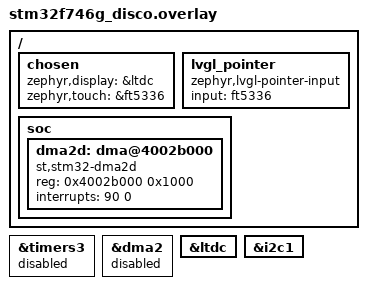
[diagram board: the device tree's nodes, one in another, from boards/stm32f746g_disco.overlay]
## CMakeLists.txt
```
# DSO-746 demo oscilloscope / spectrum analyser / generator
cmake_minimum_required(VERSION 3.20.0)

find_package(Zephyr REQUIRED HINTS $ENV{ZEPHYR_BASE})
project(dso746)

target_sources(app PRIVATE
  src/main.c
  src/ui.c
  src/acq.c
  src/acq_algo.c
  src/gen.c
  src/dsp.c
  src/dsp_math.c
  src/sim.c
)
target_include_directories(app PRIVATE src)
```

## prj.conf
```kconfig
# ---- kernel -----------------------------------------------------------
CONFIG_MAIN_STACK_SIZE=8192
CONFIG_MAIN_THREAD_PRIORITY=7
CONFIG_HEAP_MEM_POOL_SIZE=16384
CONFIG_CBPRINTF_FP_SUPPORT=y
CONFIG_FPU=y
CONFIG_LOG=y
CONFIG_LOG_MODE_DEFERRED=y
# stack diagnostics: the 5 s statistics line reports the free stack of every
# thread, so an overflow shows up in the console before it becomes a hang
CONFIG_THREAD_MONITOR=y
CONFIG_THREAD_NAME=y
CONFIG_THREAD_STACK_INFO=y
CONFIG_INIT_STACKS=y

# ---- cache: the ADC ring must not be cached, DMA does not see D-cache --
CONFIG_DCACHE=y
CONFIG_ICACHE=y
CONFIG_NOCACHE_MEMORY=y

# ---- display ----------------------------------------------------------
CONFIG_DISPLAY=y
CONFIG_STM32_LTDC=y
CONFIG_STM32_LTDC_RGB565=y
CONFIG_STM32_LTDC_FB_NUM=2

# ---- touch ------------------------------------------------------------
CONFIG_INPUT=y
CONFIG_I2C=y
CONFIG_INPUT_FT5336=y
CONFIG_INPUT_FT5336_INTERRUPT=y
# B1 USER key: demo <-> live
CONFIG_INPUT_GPIO_KEYS=y
CONFIG_GPIO=y

# ---- LVGL -------------------------------------------------------------
CONFIG_LVGL=y
CONFIG_LV_COLOR_DEPTH_16=y
CONFIG_LV_Z_MEM_POOL_SIZE=131072
CONFIG_LV_Z_VDB_SIZE=25
CONFIG_LV_Z_DOUBLE_VDB=y
# 256 KB of internal SRAM cannot hold the LVGL heap and two render buffers as
# well as the ADC ring; both go to SDRAM, the ring stays in SRAM on purpose
CONFIG_LV_Z_MEMORY_POOL_ZEPHYR_REGION=y
CONFIG_LV_Z_MEMORY_POOL_ZEPHYR_REGION_NAME="SDRAM1"
CONFIG_LV_Z_VDB_ZEPHYR_REGION=y
CONFIG_LV_Z_VDB_ZEPHYR_REGION_NAME="SDRAM1"
CONFIG_LV_Z_FLUSH_THREAD=y
CONFIG_LV_USE_CANVAS=y
CONFIG_LV_USE_LABEL=y
CONFIG_LV_FONT_UNSCII_8=y
CONFIG_LV_FONT_MONTSERRAT_12=y
CONFIG_LV_FONT_MONTSERRAT_14=y
CONFIG_LV_FONT_MONTSERRAT_20=y
# the phosphor halo is a shadow; caching the blur costs 16*16 = 256 bytes
# and removes the per-redraw recomputation
CONFIG_LV_DRAW_SW_COMPLEX=y
# ChromART (DMA2D) draw unit: fills, blends and blits are done by the
# accelerator, and the transfer-complete interrupt frees the CPU while it runs
CONFIG_LV_USE_DRAW_DMA2D=y
CONFIG_LV_DRAW_DMA2D_HAL_INCLUDE="stm32f7xx_hal.h"
# Synchronous, not interrupt-driven. In interrupt mode the draw unit waits on
# a semaphore that only the transfer-COMPLETE interrupt signals; a transfer
# that ends in a configuration or transfer error never signals it and the UI
# thread waits forever - exactly the FFT-settings freeze. The sync path polls
# the START bit, which hardware clears on completion AND on abort, so it can
# never hang. A blit is microseconds either way.
CONFIG_LV_USE_DRAW_DMA2D_INTERRUPT=n
CONFIG_LV_DRAW_SW_SHADOW_CACHE_SIZE=16

# ---- DSP --------------------------------------------------------------
CONFIG_CMSIS_DSP=y
CONFIG_CMSIS_DSP_TRANSFORM=y
CONFIG_CMSIS_DSP_COMPLEXMATH=y
CONFIG_CMSIS_DSP_FASTMATH=y
CONFIG_CMSIS_DSP_SUPPORT=y
CONFIG_CMSIS_DSP_BASICMATH=y
CONFIG_CMSIS_DSP_STATISTICS=y

# ---- console ----------------------------------------------------------
CONFIG_SERIAL=y
CONFIG_CONSOLE=y
CONFIG_UART_CONSOLE=y
```

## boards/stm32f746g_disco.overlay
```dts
/*
 * DSO-746 board overlay.
 *
 * TIM2, TIM3, ADC1, ADC3 and DMA2 are driven directly through the LL headers,
 * so the matching Zephyr drivers are kept OUT of the way: if the Zephyr DMA
 * driver owned DMA2 it would install its own handlers on the same streams
 * and the two would fight over the interrupt.
 */

/ {
	chosen {
		zephyr,display = &ltdc;
		zephyr,touch = &ft5336;
	};

	lvgl_pointer {
		compatible = "zephyr,lvgl-pointer-input";
		input = <&ft5336>;
	};
};

/* The board devicetree enables TIM3 as a PWM provider. The generator needs
 * DMA into CCR1, which the Zephyr PWM API cannot express, so we take it over. */
&timers3 {
	status = "disabled";
};

/* Left disabled on purpose - see the comment at the top. */
&dma2 {
	status = "disabled";
};

&ltdc {
	status = "okay";
};

/*
 * Chrom-ART (DMA2D). The F7 devicetree does not declare it, but LVGL's DMA2D
 * draw unit connects its interrupt through this node label, so it is declared
 * here. Base address 0x4002B000 and interrupt line 90 come from RM0385.
 */
/ {
	soc {
		dma2d: dma@4002b000 {
			compatible = "st,stm32-dma2d";
			reg = <0x4002b000 0x1000>;
			interrupts = <90 0>;
			status = "okay";
		};
	};
};

&i2c1 {
	status = "okay";
};
```

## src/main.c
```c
/*
 * Author:  Eduard
 * Project: DSO-746 - oscilloscope, FFT analyzer and signal generator
 * Repo:    https://github.com/ed1385/dso746-zephyr
 * License: MIT
 *
 * DSO-746 - entry point.
 *
 * Thread map (priority in brackets, lower number = higher priority):
 *   DMA2 stream 4 ISR   flags the finished ring half, gives a semaphore
 *   acq  [-2]           trigger search, pre-trigger extraction, frame slots
 *   main/ui [7]         LVGL, measurements, spectrum, rendering
 *   input               FT5336 interrupt -> Zephyr input -> lv_indev
 *
 * The rule that keeps the display smooth: the UI never blocks acquisition.
 * If a frame cannot be handed over it is dropped and sampling continues.
 */
#include <zephyr/kernel.h>
#include <zephyr/irq.h>
#include <soc.h>
#include <zephyr/device.h>
#include <zephyr/drivers/display.h>
#include <zephyr/logging/log.h>
#include <lvgl.h>
#include <zephyr/input/input.h>
#include <zephyr/dt-bindings/input/input-event-codes.h>

#include "app.h"

LOG_MODULE_REGISTER(main, LOG_LEVEL_INF);

/*
 * The DMA2D draw unit installs its own interrupt handler through the dma2d
 * devicetree node declared in the board overlay, so nothing is needed here.
 */

/*
 * Two rates, on purpose.
 *
 * LVGL is serviced every 10 ms. That is what makes touch feel immediate: the
 * FT5336 raises its interrupt, the Zephyr input driver queues the event, and
 * lv_timer_handler picks it up within 10 ms instead of within a frame period.
 * Key animations - the phosphor decay - also step at this rate.
 *
 * The waveform is recomputed at 50 ms. Redrawing a trace faster than 20 Hz
 * buys nothing a human can see and costs the whole FMC budget.
 */
#define TICK_MS  10
#define FRAME_MS 50

static float spec[WAVE_COLS];

#ifdef CONFIG_THREAD_STACK_INFO
static void stack_report(const struct k_thread *t, void *arg)
{
	ARG_UNUSED(arg);
	size_t unused = 0;

	if (k_thread_stack_space_get(t, &unused) == 0) {
		const char *n = k_thread_name_get((k_tid_t)t);

		LOG_INF("  stack %-10s free %5u of %5u", n ? n : "?",
			(unsigned)unused, (unsigned)t->stack_info.size);
	}
}
#endif

/*
 * B1 USER key (PI11) toggles demo <-> live. It arrives through the Zephyr
 * input subsystem as INPUT_KEY_0, the same path the touch panel uses, so the
 * gpio-keys driver keeps owning the pin and nothing fights over the GPIO.
 */
static void key_cb(struct input_event *evt, void *user_data)
{
	ARG_UNUSED(user_data);

	if (evt->type != INPUT_EV_KEY || evt->code != INPUT_KEY_0 || evt->value == 0) {
		return;
	}

	/* Spec §1.5: this runs in the input thread. It may not touch LVGL,
	 * so it only requests the switch; the UI thread applies it. */
	ui_request_demo_toggle();
}
INPUT_CALLBACK_DEFINE(NULL, key_cb, NULL);

int main(void)
{
	const struct device *disp = DEVICE_DT_GET(DT_CHOSEN(zephyr_display));

	if (!device_is_ready(disp)) {
		LOG_ERR("display not ready");
		return -ENODEV;
	}

	ui_init();
	dsp_init();
	gen_init();
	acq_init();

	ui_lock();
	acq_apply_cfg(ui_cfg());
	bool demo = ui_cfg()->demo;

	ui_unlock();
	/* the converters run from boot in both modes: switching to live then
	 * shows a live screen immediately instead of after the first sweep */
	acq_start();
	LOG_INF("boot in %s mode, B1 USER key switches", demo ? "DEMO" : "LIVE");

	display_blanking_off(disp);
	lv_timer_handler();

	uint32_t next_tick = k_uptime_get_32();
	uint32_t next_frame = next_tick;
	uint32_t frames = 0, dropped = 0, last_stat = next_tick;

	while (true) {
		/*
		 * Input first, always. lv_timer_handler() samples the touch
		 * panel; if a frame ever takes longer than a tap, the press and
		 * the release both fall between two samples and the tap is lost.
		 * So the sampling cadence is fixed at TICK_MS and is never
		 * skipped, and the frame work is what yields, not the input.
		 */
		ui_service();
		lv_timer_handler();

		uint32_t now_ms = k_uptime_get_32();

		if ((int32_t)(now_ms - next_frame) < 0) {
			next_tick += TICK_MS;
			int32_t s2 = (int32_t)(next_tick - k_uptime_get_32());

			k_msleep(s2 > 0 ? s2 : 1);
			continue;
		}
		next_frame += FRAME_MS;

		ui_lock();
		bool sim = ui_cfg()->demo;

		ui_unlock();

		struct dso_frame *f;
		bool owned = false;          /* only real frames go back to the slab */

		if (sim) {
			/* drop anything the hardware queued before the switch */
			struct dso_frame *stale;

			while ((stale = acq_take_frame(0)) != NULL) {
				acq_release_frame(stale);
			}
			/* Generate from a COPY of the settings, outside the mutex.
			 * Holding it during ~10 ms of trigonometry let the acq
			 * thread (which takes the same mutex 430 times a second
			 * at the widest span) block on it, and priority
			 * inheritance then made this thread cooperative for the
			 * whole window - a demo-only condition the live path
			 * never creates. */
			static struct dso_cfg snap;

			ui_lock();
			snap = *ui_cfg();
			ui_unlock();
			f = sim_frame(&snap);
		} else {
			f = acq_take_frame(0);     /* never block the UI thread */
			owned = (f != NULL);
		}

		struct dso_meas m = { 0 };
		const float *sp = NULL;

		if (f) {
			/* Drain anything that piled up while we were drawing and
			 * keep only the newest: showing a stale frame is worse
			 * than showing fewer of them. */
			if (owned) {
				struct dso_frame *newer;

				while ((newer = acq_take_frame(0)) != NULL) {
					acq_release_frame(f);
					f = newer;
					dropped++;
				}
			}


			ui_lock();
			uint8_t mode = ui_cfg()->mode;
			uint8_t fsrc = ui_cfg()->fft.source;
			uint8_t win = ui_cfg()->fft.window;
			bool meas_on = ui_cfg()->meas_on;

			ui_unlock();

			if (mode == MODE_FFT) {
				uint8_t ch = fsrc < f->nch ? fsrc : 0;
				bool len_ok = false;

				for (size_t i = 0; i < fft_size_cnt; i++) {
					if (fft_size_tab[i] == f->n) {
						len_ok = true;
						break;
					}
				}
				if (len_ok) {
					dsp_spectrum(f->s[ch], f->n, win, spec, WAVE_COLS);
					sp = spec;
				}
			} else if (meas_on) {
				dsp_measure(f->s[0], f->n, f->sample_rate,
					    ADC_VREF / ADC_FULL_SCALE, 2048.0f, &m);
			}

			ui_on_frame(f, &m, sp);
			ui_sync(&m, f->sample_rate);
			if (owned) {
				acq_release_frame(f);
			}
			frames++;
		} else {
			ui_on_frame(NULL, NULL, NULL);   /* GEN / no trigger */
			ui_sync(NULL, 0.0f);
		}

		uint32_t now = k_uptime_get_32();

		if (now - last_stat >= 5000U) {
			LOG_INF("%u frames/s drawn, %u dropped, %u acq overruns",
				frames / 5U, dropped / 5U, (unsigned)acq_overruns());
#ifdef CONFIG_THREAD_STACK_INFO
			k_thread_foreach(stack_report, NULL);
#endif
			frames = dropped = 0;
			last_stat = now;
		}

		if ((int32_t)(k_uptime_get_32() - next_frame) > 0) {
			next_frame = k_uptime_get_32();  /* we are behind: resync */
		}
		next_tick = k_uptime_get_32();
	}
	return 0;
}
```

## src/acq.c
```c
/*
 * Author:  Eduard
 * Project: DSO-746 - oscilloscope, FFT analyzer and signal generator
 * Repo:    https://github.com/ed1385/dso746-zephyr
 * License: MIT
 *
 * Acquisition: TIM2 TRGO -> ADC1 (CH1, PA0) and ADC3 (CH2, PF10) -> DMA2
 * circular, half/full interrupts. Written on the LL headers on purpose:
 * Zephyr's ADC driver only offers one-shot adc_read() and cannot do
 * continuous circular DMA, which is the whole point of an oscilloscope.
 * Everything else in this application stays ordinary Zephyr.
 *
 * DMA2 is deliberately left `status = "disabled"` in the overlay so the
 * Zephyr DMA driver does not claim the same streams and interrupts.
 *
 * Streams (RM0385 table 43):
 *   ADC1 -> DMA2 stream 4, channel 0
 *   ADC3 -> DMA2 stream 1, channel 2
 */
#include <zephyr/kernel.h>
#include <zephyr/device.h>
#include <zephyr/irq.h>
#include <zephyr/logging/log.h>
#include <soc.h>
#include <stm32_ll_bus.h>
#include <stm32_ll_adc.h>
#include <stm32_ll_dma.h>
#include <stm32_ll_tim.h>
#include <stm32_ll_gpio.h>
#include <stm32_ll_rcc.h>

#include <zephyr/linker/devicetree_regions.h>

#include "app.h"

LOG_MODULE_REGISTER(acq, LOG_LEVEL_INF);

/* TIM2 sits on APB1; with APB1 prescaler 4 the timer clock is 2x APB1 */
#define TIM2_CLK_HZ   108000000U
#define ADC_CLK_HZ    27000000U        /* PCLK2 108 MHz / 4                */
#define ADC_CYCLES    15U              /* 12-bit conversion + 3 sampling   */
#define ADC_MAX_SPS   (ADC_CLK_HZ / ADC_CYCLES)   /* 1 800 000 Sa/s        */

/* The ring must not live in SDRAM: LTDC reads the framebuffer from there
 * continuously and the two would fight over FMC. It must also be outside the
 * D-cache, which DMA does not see. */
static uint16_t ring[N_CH][ADC_RING_LEN] __nocache __aligned(32);

/* a frame is extracted from ONE finished half; if this ever fails, the
 * extraction would read into the half being written */
BUILD_ASSERT(FRAME_MAX <= ADC_RING_LEN / 2, "frame must fit in half the ring");

/* frame slots are CPU-only, so they live in SDRAM; internal SRAM is reserved
 * for the DMA ring and the stacks */
static char frame_pool[FRAME_SLOTS * sizeof(struct dso_frame)]
	__attribute__((section(LINKER_DT_NODE_REGION_NAME(DT_NODELABEL(sdram1)))))
	__aligned(4);
static struct k_mem_slab frame_slab;
K_MSGQ_DEFINE(frame_q, sizeof(struct dso_frame *), FRAME_SLOTS, 4);
static K_SEM_DEFINE(half_sem, 0, 1);

static volatile uint8_t ready_half;    /* 0 = lower half, 1 = upper half   */
static volatile uint32_t overrun_cnt;
static volatile uint8_t discard_halves;  /* halves still holding old-rate samples */
static struct dso_cfg cfg_snapshot;
static bool trig_armed = true;
static float cur_sample_rate = 1.0e6f;
static uint32_t last_free_ms;

/* ---------------------------------------------------------------- clocks */
static void gpio_analog(GPIO_TypeDef *port, uint32_t pin)
{
	LL_GPIO_SetPinMode(port, pin, LL_GPIO_MODE_ANALOG);
	LL_GPIO_SetPinPull(port, pin, LL_GPIO_PULL_NO);
}

static void adc_setup(ADC_TypeDef *adc, uint32_t channel)
{
	LL_ADC_SetResolution(adc, LL_ADC_RESOLUTION_12B);
	LL_ADC_SetDataAlignment(adc, LL_ADC_DATA_ALIGN_RIGHT);
	/* the F7 LL folds the edge into the source constant; the edge is then
	 * given again to LL_ADC_REG_StartConversionExtTrig() */
	LL_ADC_REG_SetTriggerSource(adc, LL_ADC_REG_TRIG_EXT_TIM2_TRGO);
	LL_ADC_REG_SetSequencerLength(adc, LL_ADC_REG_SEQ_SCAN_DISABLE);
	LL_ADC_REG_SetSequencerRanks(adc, LL_ADC_REG_RANK_1, channel);
	LL_ADC_SetChannelSamplingTime(adc, channel, LL_ADC_SAMPLINGTIME_3CYCLES);
	LL_ADC_REG_SetContinuousMode(adc, LL_ADC_REG_CONV_SINGLE);
	LL_ADC_REG_SetDMATransfer(adc, LL_ADC_REG_DMA_TRANSFER_UNLIMITED);
	LL_ADC_Enable(adc);
}

static void dma_setup(uint32_t stream, uint32_t channel,
		      uint32_t periph_addr, uint16_t *mem)
{
	LL_DMA_DisableStream(DMA2, stream);
	while (LL_DMA_IsEnabledStream(DMA2, stream)) {
	}

	LL_DMA_SetChannelSelection(DMA2, stream, channel);
	LL_DMA_ConfigTransfer(DMA2, stream,
			      LL_DMA_DIRECTION_PERIPH_TO_MEMORY |
			      LL_DMA_MODE_CIRCULAR |
			      LL_DMA_PERIPH_NOINCREMENT |
			      LL_DMA_MEMORY_INCREMENT |
			      LL_DMA_PDATAALIGN_HALFWORD |
			      LL_DMA_MDATAALIGN_HALFWORD |
			      LL_DMA_PRIORITY_VERYHIGH);
	LL_DMA_ConfigAddresses(DMA2, stream, periph_addr, (uint32_t)mem,
			       LL_DMA_DIRECTION_PERIPH_TO_MEMORY);
	LL_DMA_SetDataLength(DMA2, stream, ADC_RING_LEN);
	LL_DMA_DisableFifoMode(DMA2, stream);
}

/* Only the CH1 stream raises interrupts. CH2 runs on the same TIM2 trigger
 * with the same length, so its write pointer is at the same offset - one
 * interrupt source is enough and halves the ISR load. */
static void dma_ch1_isr(const void *arg)
{
	ARG_UNUSED(arg);

	if (LL_DMA_IsActiveFlag_HT4(DMA2)) {
		LL_DMA_ClearFlag_HT4(DMA2);
		ready_half = 0;
		if (k_sem_count_get(&half_sem)) {
			overrun_cnt++;      /* the trigger thread fell behind */
		}
		k_sem_give(&half_sem);
	}
	if (LL_DMA_IsActiveFlag_TC4(DMA2)) {
		LL_DMA_ClearFlag_TC4(DMA2);
		ready_half = 1;
		if (k_sem_count_get(&half_sem)) {
			overrun_cnt++;
		}
		k_sem_give(&half_sem);
	}
	if (LL_DMA_IsActiveFlag_TE4(DMA2)) {
		LL_DMA_ClearFlag_TE4(DMA2);
		LOG_ERR("DMA transfer error");
	}
}

/* --------------------------------------------------------------- control */
static uint32_t rate_to_arr(float sps)
{
	if (sps > (float)ADC_MAX_SPS) {
		sps = (float)ADC_MAX_SPS;
	}
	if (sps < 1000.0f) {
		sps = 1000.0f;
	}
	uint32_t div = (uint32_t)((float)TIM2_CLK_HZ / sps + 0.5f);

	return div ? div - 1U : 0U;
}

void acq_apply_cfg(const struct dso_cfg *cfg)
{
	cfg_snapshot = *cfg;

	uint8_t idx = cfg->tdiv_idx;
	uint8_t min_idx = (uint8_t)tdiv_min_idx(false);   /* two channels */

	if (idx < min_idx) {
		idx = min_idx;
	}
	if (cfg->mode == MODE_FFT) {
		uint8_t si = cfg->fft.span_idx < FFT_SPAN_CNT ? cfg->fft.span_idx : 0;

		cur_sample_rate = fft_rate_tab[si];
	} else {
		acq_plan(idx, &cur_sample_rate);
	}

	uint32_t arr = rate_to_arr(cur_sample_rate);

	LL_TIM_SetAutoReload(TIM2, arr);
	LL_TIM_GenerateEvent_UPDATE(TIM2);
	/* the ring keeps running: the half being written and the next one
	 * still hold samples taken at the previous rate. A frame built from
	 * them would carry the new rate with old spacing - a one-frame flash
	 * of wrong time scale. Skip them. */
	discard_halves = 2;
	LOG_INF("timebase %.1f us/div, %u Sa/s, ARR %u",
		(double)(tdiv_tab[idx] * 1e6f), (unsigned)cur_sample_rate, arr);
}

void acq_start(void)
{
	LL_TIM_EnableCounter(TIM2);
	LL_ADC_REG_StartConversionExtTrig(ADC1, LL_ADC_REG_TRIG_EXT_RISING);
	LL_ADC_REG_StartConversionExtTrig(ADC3, LL_ADC_REG_TRIG_EXT_RISING);
}

void acq_stop(void)
{
	LL_TIM_DisableCounter(TIM2);
}

/* ------------------------------------------------------------ trigger job */
static uint16_t level_to_code(const struct dso_cfg *c)
{
	/* volts -> ADC code, using the same scale the UI displays */
	float lsb = ADC_VREF / ADC_FULL_SCALE;
	float code = 2048.0f + c->trig.level_v / lsb;

	if (code < 0.0f) {
		code = 0.0f;
	}
	if (code > ADC_FULL_SCALE) {
		code = ADC_FULL_SCALE;
	}
	return (uint16_t)code;
}

static void acq_thread(void *a, void *b, void *c)
{
	ARG_UNUSED(a); ARG_UNUSED(b); ARG_UNUSED(c);

	const size_t half = ADC_RING_LEN / 2;

	while (true) {
		k_sem_take(&half_sem, K_FOREVER);

		/* copy only what a sweep needs, under the lock for as short a
		 * time as possible: this runs up to 430 times a second */
		struct dso_cfg cfg;

		ui_lock();
		cfg.running = ui_cfg()->running;
		cfg.mode = ui_cfg()->mode;
		cfg.tdiv_idx = ui_cfg()->tdiv_idx;
		cfg.hpos_div = ui_cfg()->hpos_div;
		cfg.trig = ui_cfg()->trig;
		cfg.fft = ui_cfg()->fft;
		cfg.ch[1].on = ui_cfg()->ch[1].on;
		ui_unlock();

		if (!cfg.running && cfg.mode != MODE_FFT) {
			continue;
		}

		size_t base = ready_half ? half : 0;
		size_t want;
		float sr_unused;

		if (cfg.mode == MODE_FFT) {
			want = fft_size_tab[cfg.fft.size_idx];
		} else {
			want = acq_plan(cfg.tdiv_idx, &sr_unused);
		}
		if (want > FRAME_MAX) {
			want = FRAME_MAX;
		}
		size_t pre = (cfg.mode == MODE_FFT) ? 0
						    : acq_pretrigger(want, cfg.hpos_div);
		uint8_t src = cfg.trig.source < N_CH ? cfg.trig.source : 0;

		/* the whole window [trig - pre, trig - pre + want) must lie
		 * inside the half that is finished: pre-trigger samples before
		 * `base` would come from the half the DMA is writing right now */
		size_t search_begin = base + pre + 1;
		size_t search_end = base + half - (want - pre);
		int trig = -1;

		if (cfg.mode == MODE_SCOPE && search_end > search_begin) {
			trig = acq_find_trigger(ring[src], ADC_RING_LEN,
						search_begin, search_end,
						level_to_code(&cfg),
						cfg.trig.hyst_lsb,
						cfg.trig.slope, &trig_armed);
		}

		uint32_t now = k_uptime_get_32();
		bool auto_sweep = false;

		if (trig < 0) {
			if (cfg.mode == MODE_FFT) {
				trig = (int)(base + pre);          /* free run */
			} else if (cfg.trig.mode == 0) {
				/*
				 * AUTO means free-running sweep when nothing
				 * crosses the level - that is how the noise and
				 * the mains pickup on an open input become
				 * visible. The old code gated this on the time
				 * since the LAST FRAME, and since auto frames
				 * refreshed that timestamp too, the gate could
				 * hold shut and the screen stayed empty.
				 */
				if ((now - last_free_ms) < 40U) {
					continue;
				}
				last_free_ms = now;
				trig = (int)(base + pre);
				auto_sweep = true;
			} else {
				continue;                          /* NORMAL: wait */
			}
		}

		/* holdoff: ignore triggers that arrive too soon after the last */
		if (cfg.trig.holdoff_us > 1000U && !auto_sweep) {
			static uint32_t prev_ms;

			if ((now - prev_ms) < cfg.trig.holdoff_us / 1000U) {
				continue;
			}
			prev_ms = now;
		}

		struct dso_frame *f;

		if (k_mem_slab_alloc(&frame_slab, (void **)&f, K_NO_WAIT) != 0) {
			continue;      /* UI is behind: drop the frame, keep sampling */
		}

		f->n = (uint16_t)want;
		f->nch = (cfg.ch[1].on ? 2 : 1);
		f->triggered = !auto_sweep;
		f->sample_rate = cur_sample_rate;

		for (uint8_t ch = 0; ch < f->nch; ch++) {
			acq_extract(ring[ch], ADC_RING_LEN, (size_t)trig, pre,
				    f->s[ch], want);
		}

		if (k_msgq_put(&frame_q, &f, K_NO_WAIT) != 0) {
			k_mem_slab_free(&frame_slab, (void *)f);
		}

		if (cfg.trig.mode == 2 && f->triggered) {     /* SINGLE */
			ui_lock();
			ui_cfg()->running = false;
			ui_unlock();
		}
	}
}

K_THREAD_STACK_DEFINE(acq_stack, 2048);
static struct k_thread acq_thread_data;

uint32_t acq_overruns(void)
{
	return overrun_cnt;
}

struct dso_frame *acq_take_frame(int timeout_ms)
{
	struct dso_frame *f;

	if (k_msgq_get(&frame_q, &f, K_MSEC(timeout_ms)) == 0) {
		return f;
	}
	return NULL;
}

void acq_release_frame(struct dso_frame *f)
{
	k_mem_slab_free(&frame_slab, (void *)f);
}

int acq_init(void)
{
	k_mem_slab_init(&frame_slab, frame_pool, sizeof(struct dso_frame),
			FRAME_SLOTS);

	LL_AHB1_GRP1_EnableClock(LL_AHB1_GRP1_PERIPH_GPIOA);
	LL_AHB1_GRP1_EnableClock(LL_AHB1_GRP1_PERIPH_GPIOF);
	LL_AHB1_GRP1_EnableClock(LL_AHB1_GRP1_PERIPH_DMA2);
	LL_APB2_GRP1_EnableClock(LL_APB2_GRP1_PERIPH_ADC1);
	LL_APB2_GRP1_EnableClock(LL_APB2_GRP1_PERIPH_ADC3);
	LL_APB1_GRP1_EnableClock(LL_APB1_GRP1_PERIPH_TIM2);

	gpio_analog(GPIOA, LL_GPIO_PIN_0);    /* CH1, Arduino A0, ADC123_IN0 */
	gpio_analog(GPIOF, LL_GPIO_PIN_10);   /* CH2, Arduino A1, ADC3_IN8   */

	LL_ADC_SetCommonClock(__LL_ADC_COMMON_INSTANCE(ADC1),
			      LL_ADC_CLOCK_SYNC_PCLK_DIV4);

	/* TIM2 only produces TRGO; nothing is routed to a pin */
	LL_TIM_SetPrescaler(TIM2, 0);
	LL_TIM_SetAutoReload(TIM2, 59);        /* 1.8 MSa/s until reprogrammed */
	LL_TIM_SetTriggerOutput(TIM2, LL_TIM_TRGO_UPDATE);
	LL_TIM_EnableARRPreload(TIM2);
	LL_TIM_GenerateEvent_UPDATE(TIM2);

	dma_setup(LL_DMA_STREAM_4, LL_DMA_CHANNEL_0,
		  LL_ADC_DMA_GetRegAddr(ADC1, LL_ADC_DMA_REG_REGULAR_DATA),
		  ring[0]);
	dma_setup(LL_DMA_STREAM_1, LL_DMA_CHANNEL_2,
		  LL_ADC_DMA_GetRegAddr(ADC3, LL_ADC_DMA_REG_REGULAR_DATA),
		  ring[1]);

	LL_DMA_EnableIT_HT(DMA2, LL_DMA_STREAM_4);
	LL_DMA_EnableIT_TC(DMA2, LL_DMA_STREAM_4);
	LL_DMA_EnableIT_TE(DMA2, LL_DMA_STREAM_4);

	IRQ_CONNECT(DMA2_Stream4_IRQn, 1, dma_ch1_isr, NULL, 0);
	irq_enable(DMA2_Stream4_IRQn);

	LL_DMA_EnableStream(DMA2, LL_DMA_STREAM_4);
	LL_DMA_EnableStream(DMA2, LL_DMA_STREAM_1);

	adc_setup(ADC1, LL_ADC_CHANNEL_0);
	adc_setup(ADC3, LL_ADC_CHANNEL_8);
	k_busy_wait(10);                       /* tSTAB after ADC enable */

	/* Highest PREEMPTIBLE priority, not cooperative. A cooperative thread
	 * that blocks on the settings mutex boosts the UI thread to cooperative
	 * while it holds the lock, and then nothing - flush, input, logging -
	 * can run until the lock is released. Preemptible keeps the trigger
	 * search prompt without ever freezing the rest of the system. */
	k_thread_create(&acq_thread_data, acq_stack, K_THREAD_STACK_SIZEOF(acq_stack),
			acq_thread, NULL, NULL, NULL, 1, 0, K_NO_WAIT);
	k_thread_name_set(&acq_thread_data, "acq");

	LOG_INF("acquisition ready, max %u Sa/s per channel", ADC_MAX_SPS);
	return 0;
}
```

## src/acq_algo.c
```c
/*
 * Author:  Eduard
 * Project: DSO-746 - oscilloscope, FFT analyzer and signal generator
 * Repo:    https://github.com/ed1385/dso746-zephyr
 * License: MIT
 *
 * Trigger search, pre-trigger extraction and column reduction.
 * No hardware here on purpose: tests/host compiles this file directly.
 */
#include "app.h"

/* 1-2-5 ladders, shared with the UI so the displayed value and the value
 * the hardware is programmed with can never drift apart. */
const float vdiv_tab[] = { 0.02f, 0.05f, 0.1f, 0.2f, 0.5f, 1.0f, 2.0f };
const size_t vdiv_cnt = sizeof(vdiv_tab) / sizeof(vdiv_tab[0]);

/*
 * The ladder starts where the hardware can actually deliver one sample per
 * pixel column: WAVE_COLS columns over 12 divisions.
 *   1.8 MSa/s (two channels)      -> 336/(12*1.8e6)  = 15.6 us/div
 *   5.4 MSa/s (one channel, x3)   -> 336/(12*5.4e6)  =  5.2 us/div
 * so 10 us/div is the fastest 1-2-5 step that is honestly filled; a
 * 5 us/div step would need the 8-bit triple-interleaved mode (7.4 MSa/s).
 * Anything faster would be drawn from interpolated points, so it is simply
 * not offered. TDIV_MIN_DUAL is the first index legal with two channels.
 */
const float tdiv_tab[] = {
	1e-5f, 2e-5f, 5e-5f, 1e-4f, 2e-4f, 5e-4f,
	1e-3f, 2e-3f, 5e-3f, 1e-2f, 2e-2f, 5e-2f, 1e-1f,
};
const size_t tdiv_cnt = sizeof(tdiv_tab) / sizeof(tdiv_tab[0]);

size_t tdiv_min_idx(bool interleaved)
{
	return interleaved ? 0 : TDIV_MIN_DUAL;
}

const uint16_t fft_size_tab[] = { 256, 512, 1024, 2048, 4096 };

const float fft_rate_tab[FFT_SPAN_CNT] = { 16384.0f, 65536.0f, 262144.0f, 1.8e6f };
const size_t fft_size_cnt = sizeof(fft_size_tab) / sizeof(fft_size_tab[0]);

size_t acq_plan(uint8_t tdiv_idx, float *sample_rate)
{
	if (tdiv_idx >= tdiv_cnt) {
		tdiv_idx = (uint8_t)(tdiv_cnt - 1);
	}
	float screen = 12.0f * tdiv_tab[tdiv_idx];
	size_t k = 4;

	/* the most oversampling the ADC can afford for this sweep */
	while (k > 1 && (float)(WAVE_COLS * k) / screen > 1.8e6f) {
		k--;
	}
	size_t n = WAVE_COLS * k;
	float sr = (float)n / screen;

	if (sr > 1.8e6f) {
		sr = 1.8e6f;
	}
	if (sr < 1000.0f) {
		sr = 1000.0f;         /* slowest TIM2 rate we bother with */
	}
	*sample_rate = sr;
	return n;
}

size_t acq_pretrigger(size_t n, float hpos_div)
{
	float pre = (float)n / 4.0f + hpos_div * (float)n / 12.0f;

	if (pre < 0.0f) {
		return 0;
	}
	if (pre > (float)(n - 1)) {
		return n - 1;
	}
	return (size_t)pre;
}

int acq_find_trigger(const uint16_t *ring, size_t ring_len,
		     size_t from, size_t to,
		     uint16_t level, uint16_t hyst, uint8_t slope,
		     bool *armed)
{
	if (to > ring_len || from == 0 || from >= to) {
		return -1;
	}

	for (size_t i = from; i < to; i++) {
		uint16_t prev = ring[i - 1];
		uint16_t cur  = ring[i];

		if (!*armed) {
			/* re-arm only after the signal left the hysteresis band */
			if (slope == 0 && cur < (int)level - (int)hyst) {
				*armed = true;
			} else if (slope == 1 && cur > (int)level + (int)hyst) {
				*armed = true;
			} else if (slope == 2 &&
				   (cur < (int)level - (int)hyst ||
				    cur > (int)level + (int)hyst)) {
				*armed = true;
			}
			continue;
		}

		bool rise = (prev < level && cur >= level);
		bool fall = (prev > level && cur <= level);

		if ((slope == 0 && rise) || (slope == 1 && fall) ||
		    (slope == 2 && (rise || fall))) {
			*armed = false;
			return (int)i;
		}
	}
	return -1;
}

void acq_extract(const uint16_t *ring, size_t ring_len,
		 size_t trig, size_t pre, uint16_t *out, size_t n)
{
	size_t start = (trig + ring_len - (pre % ring_len)) % ring_len;

	for (size_t i = 0; i < n; i++) {
		size_t idx = start + i;

		while (idx >= ring_len) {
			idx -= ring_len;
		}
		out[i] = ring[idx];
	}
}

void acq_reduce_minmax(const uint16_t *src, size_t n,
		       uint16_t *ymin, uint16_t *ymax, size_t cols)
{
	if (cols == 0) {
		return;
	}
	if (n == 0) {
		for (size_t c = 0; c < cols; c++) {
			ymin[c] = ymax[c] = 0;
		}
		return;
	}

	for (size_t c = 0; c < cols; c++) {
		size_t a = (n * c) / cols;
		size_t b = (n * (c + 1)) / cols;

		if (b <= a) {
			b = a + 1;
		}
		if (b > n) {
			b = n;
		}

		uint16_t mn = src[a], mx = src[a];

		for (size_t i = a + 1; i < b; i++) {
			if (src[i] < mn) {
				mn = src[i];
			}
			if (src[i] > mx) {
				mx = src[i];
			}
		}
		ymin[c] = mn;
		ymax[c] = mx;
	}
}
```

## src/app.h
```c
/*
 * Author:  Eduard
 * Project: DSO-746 - oscilloscope, FFT analyzer and signal generator
 * Repo:    https://github.com/ed1385/dso746-zephyr
 * License: MIT
 *
 * DSO-746 - demo oscilloscope / spectrum analyser / generator
 * Shared types. Everything the UI can change lives in dso_cfg_t; the
 * acquisition and generator modules read it under one mutex.
 */
#ifndef DSO_APP_H
#define DSO_APP_H

#include <stdint.h>
#include <stdbool.h>
#include <stddef.h>

/* ---- panel geometry (must match the approved mockup) ------------------- */
#define SCR_W        480
#define SCR_H        272
#define WAVE_X       0
#define WAVE_Y       22
#define WAVE_W       336          /* 12 divisions x 28 px */
#define WAVE_H       192          /*  8 divisions x 24 px */
#define DIV_X        28
#define DIV_Y        24
#define WAVE_COLS    WAVE_W

/* ---- acquisition sizes ------------------------------------------------- */
#define ADC_RING_LEN   8192       /* samples per channel, two halves.        */
/* Kept at 8192: the non-cached MPU region must be power-of-two aligned, so a
 * 16384-sample ring would reserve 128 KB of the 256 KB internal SRAM. */
#define FRAME_MAX      4096       /* samples handed to the UI/DSP per frame */
#define FRAME_SLOTS    3
#define N_CH           2

#define ADC_FULL_SCALE 4095.0f
#define ADC_VREF       3.3f

/*
 * FFT span ladder. The span is set by the sample rate: Nyquist = rate / 2.
 * 8 kHz is the demo default (1 kHz sits at 1/8 of the width); the top step
 * is the full 1.8 MSa/s of the ADC, i.e. a 900 kHz span.
 */
#define FFT_SPAN_CNT 4
extern const float fft_rate_tab[FFT_SPAN_CNT];
#define FFT_SAMPLE_RATE fft_rate_tab[0]

/* ---- modes and groups -------------------------------------------------- */
enum dso_mode { MODE_SCOPE = 0, MODE_FFT, MODE_GEN, MODE_COUNT };

/* ---- user settings ----------------------------------------------------- */
struct dso_chan {
	bool     on;
	uint8_t  vdiv_idx;      /* index into vdiv_tab[]                      */
	float    offset_div;    /* -4 .. +4 divisions                          */
	uint8_t  coupling;      /* 0 DC, 1 AC, 2 GND (GPIO on the future AFE)  */
	bool     probe_x10;
	bool     bw_limit;
	bool     invert;
};

struct dso_trig {
	float    level_v;
	uint8_t  slope;         /* 0 rising, 1 falling, 2 both                 */
	uint8_t  mode;          /* 0 auto, 1 normal, 2 single                  */
	uint8_t  source;        /* 0 CH1, 1 CH2, 2 EXT                         */
	uint8_t  hyst_lsb;      /* hysteresis in ADC LSB                       */
	uint32_t holdoff_us;
};

struct dso_fft {
	uint8_t  source;
	uint8_t  size_idx;      /* index into fft_size_tab[]                   */
	uint8_t  window;        /* 0 rect, 1 hann, 2 hamming, 3 blackman-h, 4 flat-top */
	int8_t   ref_db;
	uint8_t  db_div_idx;
	uint8_t  avg_idx;
	bool     waterfall;
	uint8_t  palette;
	bool     peak_search;
	uint8_t  span_idx;      /* index into fft_rate_tab[]                   */
};

struct dso_gen {
	uint8_t  wave;          /* 0 sine .. 8 arb                             */
	float    freq_hz;
	float    ampl_vpp;
	float    offset_v;
	float    duty_pct;
	uint16_t phase_deg;
	bool     out_on;
	bool     pwm_on;        /* the hard square on the same pin group       */
	float    pwm_freq_hz;
	float    pwm_duty_pct;
};

struct dso_cfg {
	uint8_t  mode;
	uint8_t  tdiv_idx;      /* index into tdiv_tab[]                       */
	float    hpos_div;
	uint8_t  acq_mode;      /* 0 normal, 1 peak, 2 average, 3 hi-res, 4 envelope */
	uint8_t  avg_idx;
	uint8_t  mem_idx;
	bool     running;
	bool     demo;          /* B1 USER key toggles; true at boot          */
	uint8_t  persist_idx;
	bool     xy_mode;
	uint8_t  grid_mode;
	bool     meas_on;
	struct dso_chan ch[N_CH];
	struct dso_trig trig;
	struct dso_fft  fft;
	struct dso_gen  gen;
};

/* ladders shared by the UI and the acquisition */
extern const float    vdiv_tab[];      /* volts per division      */
extern const size_t   vdiv_cnt;
extern const float    tdiv_tab[];      /* seconds per division    */
extern const size_t   tdiv_cnt;
#define TDIV_MIN_DUAL 1                /* 20 us/div: slowest index legal at 1.8 MSa/s */
size_t tdiv_min_idx(bool interleaved); /* first index the hardware can really fill    */
extern const uint16_t fft_size_tab[];
extern const size_t   fft_size_cnt;

/* ---- one captured frame ------------------------------------------------ */
struct dso_frame {
	uint16_t n;                    /* valid samples per channel            */
	uint8_t  nch;
	bool     triggered;
	float    sample_rate;
	uint16_t s[N_CH][FRAME_MAX];
};

/* ---- measurements ------------------------------------------------------ */
struct dso_meas {
	float vpp, vmax, vmin, vavg, vrms;
	float freq_hz, duty_pct;
	bool  valid;
};

/* =======================================================================
 * Hardware-free algorithms. These are compiled both into the firmware and
 * into tests/host, so they can be verified without a board.
 * ======================================================================= */

/*
 * Search a rising/falling crossing of `level` inside ring[from..to) with
 * hysteresis. `armed` carries the arming state between calls exactly like
 * the reference project does: we only re-arm after the signal has gone
 * past level -/+ hyst, so a single noisy edge cannot produce a burst of
 * triggers. Returns the ring index of the crossing or -1.
 */
int  acq_find_trigger(const uint16_t *ring, size_t ring_len,
		      size_t from, size_t to,
		      uint16_t level, uint16_t hyst, uint8_t slope,
		      bool *armed);

/*
 * Sweep planner shared by the hardware, the simulator and the tests.
 * Returns the record length for one screen (12 divisions) and the sample
 * rate to run at. The record is WAVE_COLS x k samples, k = 1..4, so that the
 * min/max reduction to one column per pixel keeps spikes at slow sweeps while
 * fast sweeps still fit the 1.8 MSa/s ceiling at one sample per column.
 */
size_t acq_plan(uint8_t tdiv_idx, float *sample_rate);

/* Pre-trigger samples for a record of n samples and a horizontal position in
 * divisions: 25 % of the record at hpos 0, shifted by hpos divisions. */
size_t acq_pretrigger(size_t n, float hpos_div);

/* Copy `n` samples starting `pre` samples before `trig`, wrapping the ring. */
void acq_extract(const uint16_t *ring, size_t ring_len,
		 size_t trig, size_t pre, uint16_t *out, size_t n);

/*
 * Reduce n samples to `cols` min/max pairs - what a real DSO does so that
 * spikes survive decimation. ymin/ymax are ADC codes.
 */
void acq_reduce_minmax(const uint16_t *src, size_t n,
		       uint16_t *ymin, uint16_t *ymax, size_t cols);

/* Measurements over one frame. lsb_volts converts an ADC code to volts. */
void dsp_measure(const uint16_t *s, size_t n, float sample_rate,
		 float lsb_volts, float zero_code, struct dso_meas *m);

/* ---- module entry points ---------------------------------------------- */
int  acq_init(void);
void acq_apply_cfg(const struct dso_cfg *cfg);   /* reprograms TIM2/ADC     */
void acq_start(void);
void acq_stop(void);
struct dso_frame *acq_take_frame(int timeout_ms); /* NULL if none           */
uint32_t acq_overruns(void);                       /* ISR ran ahead of acq   */
void acq_release_frame(struct dso_frame *f);

int  gen_init(void);
void gen_apply(const struct dso_gen *g);

int  dsp_init(void);
/* Fills `out_db` with `cols` magnitude values in dB, from the frame. */
void dsp_spectrum(const uint16_t *s, size_t n, uint8_t window,
		  float *out_db, size_t cols);

struct dso_frame *sim_frame(const struct dso_cfg *cfg);

int  ui_init(void);
void ui_on_frame(struct dso_frame *f, const struct dso_meas *m,
		 const float *spec_db);
void ui_sync(const struct dso_meas *m, float sample_rate);
void ui_clear_display(void);
void ui_request_demo_toggle(void);   /* safe from any thread            */
void ui_service(void);               /* UI thread: applies requests,    *
				      * popup timeout, no-data watchdog */
struct dso_cfg *ui_cfg(void);            /* the single settings instance    */
void ui_lock(void);
void ui_unlock(void);

#endif /* DSO_APP_H */
```

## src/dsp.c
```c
/*
 * Author:  Eduard
 * Project: DSO-746 - oscilloscope, FFT analyzer and signal generator
 * Repo:    https://github.com/ed1385/dso746-zephyr
 * License: MIT
 *
 * Spectrum analysis with CMSIS-DSP. arm_rfft_fast_f32 on a 216 MHz Cortex-M7
 * with FPU takes well under a millisecond at 2048 points, so the spectrum is
 * limited by the 20 Hz display rate, not by the maths.
 */
#include <zephyr/kernel.h>
#include <zephyr/logging/log.h>
#include <arm_math.h>
#include <zephyr/linker/devicetree_regions.h>
#include <math.h>

#ifndef M_PI
#define M_PI 3.14159265358979323846
#endif

#include "app.h"

LOG_MODULE_REGISTER(dsp, LOG_LEVEL_INF);

#define FFT_MAX 4096

static arm_rfft_fast_instance_f32 rfft[5];   /* one per size in fft_size_tab */
static bool rfft_ok[5];

/* 56 KB of working arrays. They are touched by the CPU only and at 20 Hz, so
 * SDRAM costs nothing measurable; internal SRAM is needed for the DMA ring,
 * whose non-cached MPU region already has to be power-of-two aligned. */
#define SDRAM_SECTION __attribute__((section(LINKER_DT_NODE_REGION_NAME(DT_NODELABEL(sdram1)))))

static float32_t fin[FFT_MAX] SDRAM_SECTION __aligned(4);
static float32_t fout[FFT_MAX] SDRAM_SECTION __aligned(4);
static float32_t mag[FFT_MAX / 2] SDRAM_SECTION __aligned(4);
static float32_t win_tab[FFT_MAX] SDRAM_SECTION;
static uint16_t  win_len;
static uint8_t   win_kind = 0xFF;

int dsp_init(void)
{
	for (size_t i = 0; i < fft_size_cnt; i++) {
		rfft_ok[i] = (arm_rfft_fast_init_f32(&rfft[i], fft_size_tab[i])
			      == ARM_MATH_SUCCESS);
		if (!rfft_ok[i]) {
			LOG_WRN("no FFT table for %u points", fft_size_tab[i]);
		}
	}
	return 0;
}

/* Coherent gain of each window, so the peak height stays honest when the
 * window is changed. Rectangular is 1 by definition. */
static const float win_gain[5] = { 1.0f, 0.5f, 0.54f, 0.42f, 0.2156f };

static void make_window(uint8_t kind, uint16_t n)
{
	if (kind == win_kind && n == win_len) {
		return;
	}
	for (uint16_t i = 0; i < n; i++) {
		float x = 2.0f * (float)M_PI * i / (n - 1);

		switch (kind) {
		case 1: win_tab[i] = 0.5f - 0.5f * cosf(x); break;               /* Hann */
		case 2: win_tab[i] = 0.54f - 0.46f * cosf(x); break;             /* Hamming */
		case 3: win_tab[i] = 0.35875f - 0.48829f * cosf(x)
					+ 0.14128f * cosf(2 * x)
					- 0.01168f * cosf(3 * x); break;         /* Blackman-Harris */
		case 4: win_tab[i] = 0.21557f - 0.41663f * cosf(x)
					+ 0.27726f * cosf(2 * x)
					- 0.08357f * cosf(3 * x)
					+ 0.00695f * cosf(4 * x); break;         /* flat top */
		default: win_tab[i] = 1.0f; break;
		}
	}
	win_kind = kind;
	win_len = n;
}

void dsp_spectrum(const uint16_t *s, size_t n, uint8_t window,
		  float *out_db, size_t cols)
{
	size_t idx = fft_size_cnt;      /* sentinel: not found */

	for (size_t i = 0; i < fft_size_cnt; i++) {
		if (fft_size_tab[i] == n) {
			idx = i;
			break;
		}
	}
	/* n must be exactly one of the supported lengths and fit the tables;
	 * a stale length from a mode change lands here and draws a floor
	 * instead of transforming a mismatched buffer */
	if (idx == fft_size_cnt || !rfft_ok[idx] || n > FFT_MAX) {
		for (size_t c = 0; c < cols; c++) {
			out_db[c] = -140.0f;
		}
		return;
	}

	if (window > 4) {
		window = 1;
	}
	make_window(window, (uint16_t)n);

	const float lsb = ADC_VREF / ADC_FULL_SCALE;

	/* remove the DC pedestal before windowing, otherwise the window
	 * smears mid-scale across the first bins and buries small signals */
	float mean = 0.0f;

	for (size_t i = 0; i < n; i++) {
		mean += (float)s[i];
	}
	mean /= (float)n;

	for (size_t i = 0; i < n; i++) {
		fin[i] = ((float)s[i] - mean) * lsb * win_tab[i];
	}

	arm_rfft_fast_f32(&rfft[idx], fin, fout, 0);
	arm_cmplx_mag_f32(fout, mag, n / 2);

	const float scale = 2.0f / ((float)n * win_gain[window]);
	size_t bins = n / 2;

	for (size_t c = 0; c < cols; c++) {
		size_t a = (bins * c) / cols;
		size_t b = (bins * (c + 1)) / cols;

		if (b <= a) {
			b = a + 1;
		}
		float peak = 0.0f;

		for (size_t i = a; i < b && i < bins; i++) {
			if (mag[i] > peak) {
				peak = mag[i];
			}
		}
		float v = peak * scale;

		out_db[c] = (v > 1e-7f) ? 20.0f * log10f(v) : -140.0f;
	}
}
```

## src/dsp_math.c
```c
/*
 * Author:  Eduard
 * Project: DSO-746 - oscilloscope, FFT analyzer and signal generator
 * Repo:    https://github.com/ed1385/dso746-zephyr
 * License: MIT
 *
 * Automatic measurements. Deliberately free of hardware and of CMSIS-DSP so
 * the same code runs in tests/host.
 */
#include "app.h"
#include <math.h>

void dsp_measure(const uint16_t *s, size_t n, float sample_rate,
		 float lsb_volts, float zero_code, struct dso_meas *m)
{
	m->valid = false;
	if (n < 8 || sample_rate <= 0.0f) {
		return;
	}

	uint16_t mn = s[0], mx = s[0];
	double sum = 0.0, sum2 = 0.0;

	for (size_t i = 0; i < n; i++) {
		uint16_t v = s[i];

		if (v < mn) {
			mn = v;
		}
		if (v > mx) {
			mx = v;
		}
		double d = ((double)v - (double)zero_code) * (double)lsb_volts;

		sum  += d;
		sum2 += d * d;
	}

	m->vmax = ((float)mx - zero_code) * lsb_volts;
	m->vmin = ((float)mn - zero_code) * lsb_volts;
	m->vpp  = m->vmax - m->vmin;
	m->vavg = (float)(sum / n);
	m->vrms = (float)sqrt(sum2 / n);

	/*
	 * Frequency by counting mid-level crossings with a hysteresis of an
	 * eighth of the amplitude. Counting periods between the FIRST and the
	 * LAST crossing - not dividing the crossing count by the record length -
	 * removes the partial-period error that otherwise shows up as a few
	 * percent offset on short records.
	 */
	uint16_t mid  = (uint16_t)((mn + mx) / 2);
	uint16_t hyst = (uint16_t)((mx - mn) / 8);

	if (mx - mn < 16) {                 /* flat line: no frequency */
		m->freq_hz = 0.0f;
		m->duty_pct = 0.0f;
		m->valid = true;
		return;
	}

	bool armed = false;
	long first = -1, last = -1;
	unsigned periods = 0;
	size_t high_cnt = 0;

	for (size_t i = 1; i < n; i++) {
		if (s[i] > mid) {
			high_cnt++;
		}
		if (!armed) {
			if (s[i] < (int)mid - (int)hyst) {
				armed = true;
			}
			continue;
		}
		if (s[i - 1] < mid && s[i] >= mid) {
			armed = false;
			if (first < 0) {
				first = (long)i;
			} else {
				last = (long)i;
				periods++;
			}
		}
	}

	if (periods > 0 && last > first) {
		m->freq_hz = sample_rate * (float)periods / (float)(last - first);
	} else {
		m->freq_hz = 0.0f;
	}
	m->duty_pct = 100.0f * (float)high_cnt / (float)(n - 1);
	m->valid = true;
}
```

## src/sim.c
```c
/*
 * Author:  Eduard
 * Project: DSO-746 - oscilloscope, FFT analyzer and signal generator
 * Repo:    https://github.com/ed1385/dso746-zephyr
 * License: MIT
 *
 * Demo mode: synthesised signals, no hardware involved.
 *
 * The board boots into this mode so the panel is alive and every screen looks
 * the way it is meant to look even with nothing connected to the inputs.
 * The B1 USER key switches to live acquisition and back.
 *
 * The signals are deliberately chosen to exercise the whole UI:
 *   CH1  1 kHz sine with a 3rd and 5th harmonic - gives a clean trace and,
 *        in FFT mode, a fundamental plus two harmonics to find peaks on
 *   CH2  square at the same frequency with a duty that slowly sweeps
 *        30..70 %, so the duty readout visibly moves
 * Amplitude breathes slowly, so Vpp is never a frozen number, and a small
 * jitter is added so persistence looks like phosphor rather than a hard line.
 */
#include <zephyr/kernel.h>
#include <zephyr/linker/devicetree_regions.h>
#include <math.h>

#ifndef M_PI
#define M_PI 3.14159265358979323846
#endif

#include "app.h"

#define SDRAM_SECTION __attribute__((section(LINKER_DT_NODE_REGION_NAME(DT_NODELABEL(sdram1)))))

static struct dso_frame demo_frame[2] SDRAM_SECTION;
static uint8_t demo_slot;
static uint32_t rng = 0xA5A5F00D;

/* 4096-entry sine table: the demo at 4096 FFT points used to spend three
 * sinf() calls per sample - about 10 ms per frame, a fifth of the frame
 * budget, on the UI thread. A table lookup is a few cycles. */
#define SIN_N 4096
static float sin_tab[SIN_N] SDRAM_SECTION;
static bool sin_ready;

static inline float sin_lut(float ph)          /* ph in turns, any value */
{
	float t = ph - floorf(ph);
	uint32_t i = (uint32_t)(t * SIN_N) & (SIN_N - 1);

	return sin_tab[i];
}

static inline float noise(float amp)
{
	rng = rng * 1103515245u + 12345u;
	return amp * ((float)((rng >> 16) & 0xFFFF) / 32768.0f - 1.0f);
}

struct dso_frame *sim_frame(const struct dso_cfg *cfg)
{
	static float breathe;
	static float duty_ph;

	if (!sin_ready) {
		for (int i = 0; i < SIN_N; i++) {
			sin_tab[i] = sinf(2.0f * (float)M_PI * i / SIN_N);
		}
		sin_ready = true;
	}

	breathe += 0.05f;
	duty_ph += 0.013f;

	uint8_t tidx = cfg->tdiv_idx;

	if (tidx >= tdiv_cnt) {
		tidx = (uint8_t)(tdiv_cnt - 1);
	}

	/* the same rules the hardware follows: one sample per pixel column in
	 * scope mode, the fixed FFT rate in spectrum mode */
	float sr;
	size_t n;

	if (cfg->mode == MODE_FFT) {
		sr = fft_rate_tab[cfg->fft.span_idx < FFT_SPAN_CNT ? cfg->fft.span_idx : 0];
		n = fft_size_tab[cfg->fft.size_idx];
	} else {
		n = acq_plan(tidx, &sr);
	}

	if (n > FRAME_MAX) {
		n = FRAME_MAX;
	}

	const float f0 = 1000.0f;
	const float lsb = ADC_VREF / ADC_FULL_SCALE;
	/* 1.2 Vpp breathing by +-15 %, so the value moves without looking broken */
	float amp1 = (0.6f * (1.0f + 0.15f * sinf(breathe))) / lsb;
	float amp2 = 0.75f / lsb;
	float duty = 0.5f + 0.2f * sinf(duty_ph);

	/* a small phase jitter keeps the trigger looking real; the trace still
	 * stands still because the trigger point is the phase origin */
	float jit = noise(0.02f);

	/* the trigger point sits at the pre-trigger position, so the phase
	 * origin follows the horizontal position exactly as the hardware does */
	size_t pre = (cfg->mode == MODE_FFT) ? 0 : acq_pretrigger(n, cfg->hpos_div);

	struct dso_frame *fr = &demo_frame[demo_slot & 1];

	demo_slot++;

	for (size_t i = 0; i < n; i++) {
		float t = ((float)i - (float)pre) / sr;
		float turns = f0 * t + jit / (2.0f * (float)M_PI);

		float s1 = sin_lut(turns) + 0.18f * sin_lut(3.0f * turns) +
			   0.07f * sin_lut(5.0f * turns);
		float v1 = 2048.0f + amp1 * s1 + noise(6.0f);

		/* wrap into [0,1) explicitly: t is negative before the trigger
		 * point and fmodf would return a negative fraction there */
		float frac = turns - floorf(turns);      /* [0,1), any sign of t */
		float s2 = (frac < duty) ? 1.0f : -1.0f;
		float v2 = 2048.0f - 700.0f + amp2 * s2 + noise(5.0f);

		fr->s[0][i] = (uint16_t)(v1 < 0 ? 0 : (v1 > 4095 ? 4095 : v1));
		fr->s[1][i] = (uint16_t)(v2 < 0 ? 0 : (v2 > 4095 ? 4095 : v2));
	}

	fr->n = (uint16_t)n;
	fr->nch = 2;
	fr->triggered = true;
	fr->sample_rate = sr;
	return fr;
}
```
